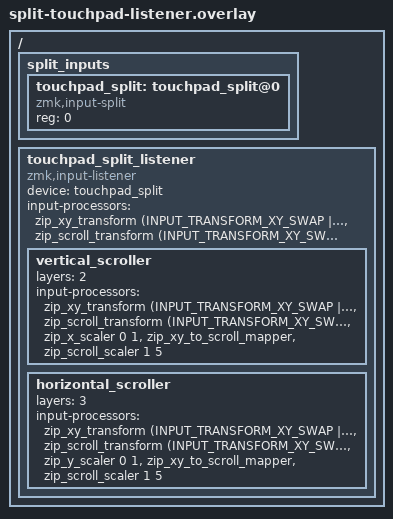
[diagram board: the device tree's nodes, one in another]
#include <input/processors.dtsi>
#include <dt-bindings/zmk/keys.h>
#include <dt-bindings/zmk/input_transform.h>
/{
    split_inputs {
        #address-cells = <1>;
        #size-cells = <0>;

        touchpad_split: touchpad_split@0 {
            compatible = "zmk,input-split";
            reg = <0>;
        };
    };

    touchpad_split_listener: touchpad_split_listener {
        compatible = "zmk,input-listener";
        device = <&touchpad_split>;
        status = "okay";
        input-processors =
            <&zip_xy_transform    (INPUT_TRANSFORM_XY_SWAP | INPUT_TRANSFORM_X_INVERT)>,
            <&zip_scroll_transform (INPUT_TRANSFORM_XY_SWAP | INPUT_TRANSFORM_X_INVERT)>;
    
        vertical_scroller {
            layers = <2>;
            input-processors =
                <&zip_xy_transform    (INPUT_TRANSFORM_XY_SWAP | INPUT_TRANSFORM_X_INVERT | INPUT_TRANSFORM_Y_INVERT)>,
                <&zip_scroll_transform (INPUT_TRANSFORM_XY_SWAP | INPUT_TRANSFORM_X_INVERT | INPUT_TRANSFORM_Y_INVERT)>,
                <&zip_x_scaler 0 1>,
                <&zip_xy_to_scroll_mapper>,
                <&zip_scroll_scaler 1 5>;
        };
    
        horizontal_scroller {
            layers = <3>;
            input-processors =
                <&zip_xy_transform    (INPUT_TRANSFORM_XY_SWAP | INPUT_TRANSFORM_X_INVERT | INPUT_TRANSFORM_Y_INVERT)>,
                <&zip_scroll_transform (INPUT_TRANSFORM_XY_SWAP | INPUT_TRANSFORM_X_INVERT | INPUT_TRANSFORM_Y_INVERT)>,
                <&zip_y_scaler 0 1>,
                <&zip_xy_to_scroll_mapper>,
                <&zip_scroll_scaler 1 5>;
        };
    };
};
